VERSION "1.0 virtual-can-dashboard"

NS_ :

BS_:

BU_: EngineECU CoolantECU AbsECU Dashboard

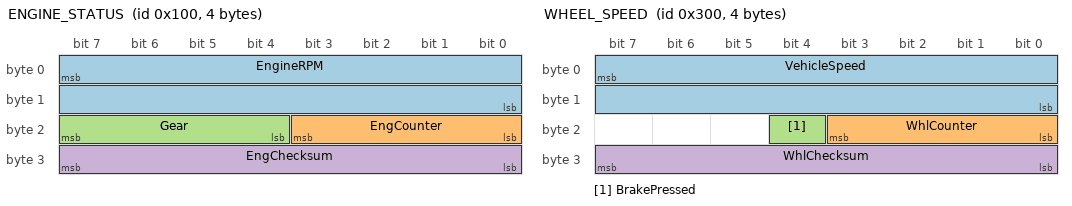
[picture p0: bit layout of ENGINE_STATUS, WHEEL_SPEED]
BO_ 256 ENGINE_STATUS: 4 EngineECU
 SG_ EngineRPM : 7|16@0+ (0.25,0) [0|8000] "rpm" Dashboard
 SG_ EngCounter : 16|4@1+ (1,0) [0|15] "" Dashboard
 SG_ Gear : 20|4@1+ (1,0) [0|5] "" Dashboard
 SG_ EngChecksum : 24|8@1+ (1,0) [0|255] "" Dashboard

BO_ 512 COOLANT: 1 CoolantECU
 SG_ CoolantTemp : 7|8@0+ (1,-40) [-40|130] "degC" Dashboard

BO_ 768 WHEEL_SPEED: 4 AbsECU
 SG_ VehicleSpeed : 7|16@0+ (0.01,0) [0|250] "km/h" Dashboard
 SG_ WhlCounter : 16|4@1+ (1,0) [0|15] "" Dashboard
 SG_ BrakePressed : 20|1@1+ (1,0) [0|1] "" Dashboard
 SG_ WhlChecksum : 24|8@1+ (1,0) [0|255] "" Dashboard

CM_ "Virtual CAN Bus Dashboard - the single source of truth for this bus.
Both the C++ ECU nodes and the Qt dashboard are written against this file.";
CM_ BO_ 256 "Engine status. Counter + checksum protected (AUTOSAR-style E2E).";
CM_ BO_ 512 "Coolant temperature. Slow, non-safety-relevant, so no E2E fields.";
CM_ BO_ 768 "Wheel speed from the ABS module. Counter + checksum protected.";
CM_ SG_ 256 EngineRPM "Crankshaft speed. 0.25 rpm per bit, big-endian in bytes 0-1.";
CM_ SG_ 256 EngCounter "Rolling 0-15 counter, low nibble of byte 2. Increments every frame.";
CM_ SG_ 256 Gear "Selected gear, high nibble of byte 2. 0 = neutral.";
CM_ SG_ 256 EngChecksum "XOR checksum of byte 3. See common/e2e.hpp.";
CM_ SG_ 512 CoolantTemp "1 degC per bit with a -40 offset, exactly like OBD-II PID 0x05.";
CM_ SG_ 768 VehicleSpeed "0.01 km/h per bit, big-endian in bytes 0-1.";
CM_ SG_ 768 WhlCounter "Rolling 0-15 counter, low nibble of byte 2.";
CM_ SG_ 768 BrakePressed "Brake pedal switch, single bit at bit 20.";
CM_ SG_ 768 WhlChecksum "XOR checksum of byte 3. See common/e2e.hpp.";

BA_DEF_ BO_  "GenMsgCycleTime" INT 0 65535;
BA_DEF_ "BusType" STRING ;
BA_DEF_DEF_  "GenMsgCycleTime" 0;
BA_DEF_DEF_  "BusType" "CAN";
BA_ "GenMsgCycleTime" BO_ 256 20;
BA_ "GenMsgCycleTime" BO_ 512 1000;
BA_ "GenMsgCycleTime" BO_ 768 20;

VAL_ 256 Gear 0 "Neutral" 1 "First" 2 "Second" 3 "Third" 4 "Fourth" 5 "Fifth" ;
VAL_ 768 BrakePressed 0 "Released" 1 "Pressed" ;
